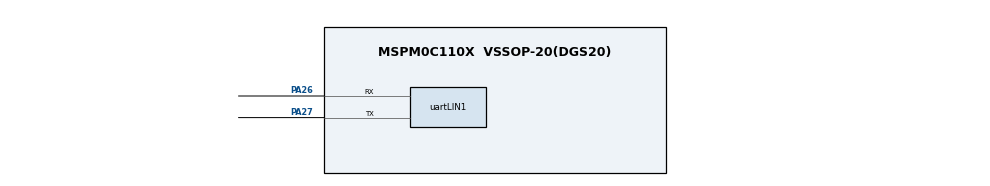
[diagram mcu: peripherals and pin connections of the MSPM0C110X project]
// @cliArgs --device "MSPM0C110X" --package "VSSOP-20(DGS20)" --part "Default"
// @cliArgs --board /ti/boards/LP_MSPM0C1104 --rtos nortos

/**
 * Import the modules used in this configuration.
 */
const Board    = scripting.addModule("/ti/driverlib/Board");
const GPIO     = scripting.addModule("/ti/driverlib/GPIO", {}, false);
const GPIO1    = GPIO.addInstance();
const GPIO2    = GPIO.addInstance();
const GPIO3    = GPIO.addInstance();
const GPIO4    = GPIO.addInstance();
const uartLIN  = scripting.addModule("/ti/driverlib/uartLIN", {}, false);
const uartLIN1 = uartLIN.addInstance();

/**
 * Write custom configuration values to the imported modules.
 */

GPIO1.$name                          = "GPIO_LEDS";
GPIO1.port                           = "PORTA";
GPIO1.associatedPins[0].invert       = "ENABLE";
GPIO1.associatedPins[0].initialValue = "SET";
GPIO1.associatedPins[0].$name        = "USER_LED_1";
GPIO1.associatedPins[0].assignedPin  = "4";

GPIO2.$name                         = "GPIO_LIN_ENABLE";
GPIO2.port                          = "PORTA";
GPIO2.portSegment                   = "Upper";
GPIO2.associatedPins[0].$name       = "USER_LIN_ENABLE";
GPIO2.associatedPins[0].assignedPin = "17";

GPIO3.$name                              = "GPIO_SWITCHES1";
GPIO3.portSegment                        = "Upper";
GPIO3.port                               = "PORTA";
GPIO3.associatedPins[0].direction        = "INPUT";
GPIO3.associatedPins[0].internalResistor = "PULL_UP";
GPIO3.associatedPins[0].assignedPin      = "16";
GPIO3.associatedPins[0].interruptEn      = true;
GPIO3.associatedPins[0].polarity         = "FALL";
GPIO3.associatedPins[0].$name            = "USER_SWITCH_1";

GPIO4.$name                              = "GPIO_INPUT";
GPIO4.associatedPins[0].$name            = "USER_INPUT_1";
GPIO4.associatedPins[0].direction        = "INPUT";
GPIO4.associatedPins[0].assignedPort     = "PORTA";
GPIO4.associatedPins[0].assignedPin      = "6";
GPIO4.associatedPins[0].internalResistor = "PULL_UP";

const SYSCTL = scripting.addModule("/ti/driverlib/SYSCTL", {}, false);

uartLIN1.$name                    = "LIN_0";
uartLIN1.targetBaudRate           = 19200;
uartLIN1.enabledInterrupts        = ["RX"];
uartLIN1.peripheral.rxPin.$assign = "PA26";
uartLIN1.peripheral.txPin.$assign = "PA27";
